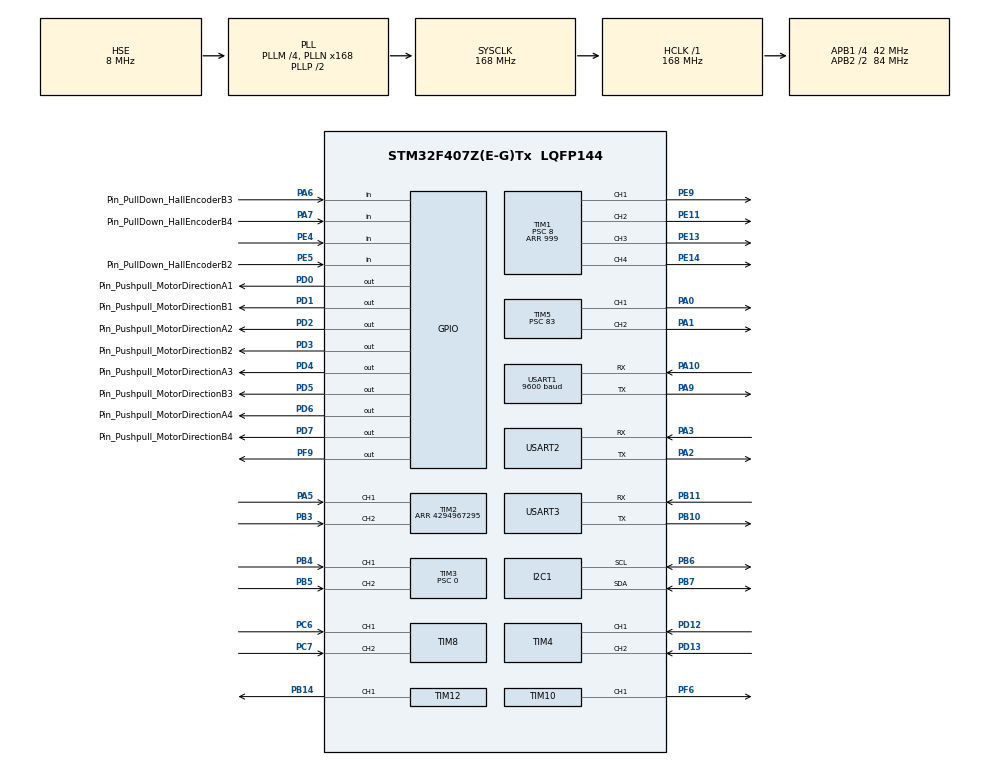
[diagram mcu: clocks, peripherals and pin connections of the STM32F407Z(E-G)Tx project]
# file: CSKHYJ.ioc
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Mcu.Family=STM32F4
Mcu.Name=STM32F407Z(E-G)Tx
Mcu.Package=LQFP144
NVIC.PriorityGroup=NVIC_PRIORITYGROUP_4
NVIC.TIM1_UP_TIM10_IRQn=true\:0\:0\:false\:false\:true\:true\:true\:true
NVIC.TIM5_IRQn=true\:2\:0\:true\:false\:true\:true\:true\:true
NVIC.TIM6_DAC_IRQn=true\:0\:0\:false\:false\:true\:true\:true\:true
NVIC.USART1_IRQn=true\:0\:0\:true\:false\:true\:true\:true\:true
NVIC.USART3_IRQn=true\:0\:0\:true\:false\:true\:true\:true\:true
PA0-WKUP.Signal=S_TIM5_CH1
PA1.Signal=S_TIM5_CH2
PA10.Mode=Asynchronous
PA10.Signal=USART1_RX
PA13.Mode=Serial_Wire
PA13.Signal=SYS_JTMS-SWDIO
PA14.Mode=Serial_Wire
PA14.Signal=SYS_JTCK-SWCLK
PA2.Mode=Asynchronous
PA2.Signal=USART2_TX
PA3.Mode=Asynchronous
PA3.Signal=USART2_RX
PA5.GPIO_PuPd=GPIO_PULLUP
PA5.Signal=S_TIM2_CH1_ETR
PA6.GPIO_Label=Pin_PullDown_HallEncoderB3
PA6.GPIO_PuPd=GPIO_PULLUP
PA6.Signal=GPIO_Input
PA7.GPIO_Label=Pin_PullDown_HallEncoderB4
PA7.GPIO_PuPd=GPIO_PULLUP
PA7.Signal=GPIO_Input
PA9.Mode=Asynchronous
PA9.Signal=USART1_TX
PB10.Mode=Asynchronous
PB10.Signal=USART3_TX
PB11.Mode=Asynchronous
PB11.Signal=USART3_RX
PB14.Signal=S_TIM12_CH1
PB3.GPIO_PuPd=GPIO_PULLUP
PB3.Signal=S_TIM2_CH2
PB4.GPIO_PuPd=GPIO_PULLUP
PB4.Signal=S_TIM3_CH1
PB5.GPIO_PuPd=GPIO_PULLUP
PB5.Signal=S_TIM3_CH2
PB6.GPIO_Pu=GPIO_PULLUP
PB6.Mode=I2C
PB6.Signal=I2C1_SCL
PB7.GPIO_Pu=GPIO_PULLUP
PB7.Mode=I2C
PB7.Signal=I2C1_SDA
PC6.GPIO_PuPd=GPIO_PULLUP
PC6.Signal=S_TIM8_CH1
PC7.GPIO_PuPd=GPIO_PULLUP
PC7.Signal=S_TIM8_CH2
PD0.GPIO_Label=Pin_Pushpull_MotorDirectionA1
PD0.Signal=GPIO_Output
PD1.GPIO_Label=Pin_Pushpull_MotorDirectionB1
PD1.Signal=GPIO_Output
PD12.GPIO_PuPd=GPIO_PULLUP
PD12.Signal=S_TIM4_CH1
PD13.GPIO_PuPd=GPIO_PULLUP
PD13.Signal=S_TIM4_CH2
PD2.GPIO_Label=Pin_Pushpull_MotorDirectionA2
PD2.Signal=GPIO_Output
PD3.GPIO_Label=Pin_Pushpull_MotorDirectionB2
PD3.Signal=GPIO_Output
PD4.GPIO_Label=Pin_Pushpull_MotorDirectionA3
PD4.Signal=GPIO_Output
PD5.GPIO_Label=Pin_Pushpull_MotorDirectionB3
PD5.Signal=GPIO_Output
PD6.GPIO_Label=Pin_Pushpull_MotorDirectionA4
PD6.Signal=GPIO_Output
PD7.GPIO_Label=Pin_Pushpull_MotorDirectionB4
PD7.Signal=GPIO_Output
PE11.Signal=S_TIM1_CH2
PE13.Signal=S_TIM1_CH3
PE14.Signal=S_TIM1_CH4
PE4.Signal=GPIO_Input
PE5.GPIO_Label=Pin_PullDown_HallEncoderB2
PE5.GPIO_PuPd=GPIO_PULLUP
PE5.Signal=GPIO_Input
PE9.Signal=S_TIM1_CH1
PF6.Signal=S_TIM10_CH1
PF9.Signal=GPIO_Output
PH0-OSC_IN.Mode=HSE-External-Oscillator
PH0-OSC_IN.Signal=RCC_OSC_IN
PH1-OSC_OUT.Mode=HSE-External-Oscillator
PH1-OSC_OUT.Signal=RCC_OSC_OUT
ProjectManager.HeapSize=0x200
ProjectManager.StackSize=0x400
ProjectManager.TargetToolchain=MDK-ARM V5.32
RCC.48MHZClocksFreq_Value=84000000
RCC.AHBFreq_Value=168000000
RCC.APB1CLKDivider=RCC_HCLK_DIV4
RCC.APB1Freq_Value=42000000
RCC.APB1TimFreq_Value=84000000
RCC.APB2CLKDivider=RCC_HCLK_DIV2
RCC.APB2Freq_Value=84000000
RCC.APB2TimFreq_Value=168000000
RCC.CortexFreq_Value=168000000
RCC.HCLKFreq_Value=168000000
RCC.HSE_VALUE=8000000
RCC.HSI_VALUE=16000000
RCC.LSE_VALUE=32768
RCC.PLLM=4
RCC.PLLN=168
RCC.PLLSourceVirtual=RCC_PLLSOURCE_HSE
RCC.SYSCLKFreq_VALUE=168000000
RCC.SYSCLKSource=RCC_SYSCLKSOURCE_PLLCLK
RCC.VCOOutputFreq_Value=336000000
SH.S_TIM10_CH1.0=TIM10_CH1,PWM Generation1 CH1
SH.S_TIM12_CH1.0=TIM12_CH1,PWM Generation1 CH1
SH.S_TIM1_CH1.0=TIM1_CH1,PWM Generation1 CH1
SH.S_TIM1_CH2.0=TIM1_CH2,PWM Generation2 CH2
SH.S_TIM1_CH3.0=TIM1_CH3,PWM Generation3 CH3
SH.S_TIM1_CH4.0=TIM1_CH4,PWM Generation4 CH4
SH.S_TIM2_CH1_ETR.0=TIM2_CH1,Encoder_Interface
SH.S_TIM2_CH2.0=TIM2_CH2,Encoder_Interface
SH.S_TIM3_CH1.0=TIM3_CH1,Encoder_Interface
SH.S_TIM3_CH2.0=TIM3_CH2,Encoder_Interface
SH.S_TIM4_CH1.0=TIM4_CH1,Encoder_Interface
SH.S_TIM4_CH2.0=TIM4_CH2,Encoder_Interface
SH.S_TIM5_CH1.0=TIM5_CH1,PWM Generation1 CH1
SH.S_TIM5_CH2.0=TIM5_CH2,PWM Generation2 CH2
SH.S_TIM8_CH1.0=TIM8_CH1,Encoder_Interface
SH.S_TIM8_CH2.0=TIM8_CH2,Encoder_Interface
TIM1.Channel-PWM\ Generation1\ CH1=TIM_CHANNEL_1
TIM1.Channel-PWM\ Generation2\ CH2=TIM_CHANNEL_2
TIM1.Channel-PWM\ Generation3\ CH3=TIM_CHANNEL_3
TIM1.Channel-PWM\ Generation4\ CH4=TIM_CHANNEL_4
TIM1.Period=999
TIM1.Prescaler=8
TIM10.Channel=TIM_CHANNEL_1
TIM10.Period=33599
TIM12.Channel-PWM\ Generation1\ CH1=TIM_CHANNEL_1
TIM12.Period=19999
TIM12.Prescaler=83
TIM2.EncoderMode=TIM_ENCODERMODE_TI12
TIM2.IC1Filter=4
TIM2.IC2Filter=4
TIM2.Period=4294967295
TIM3.EncoderMode=TIM_ENCODERMODE_TI12
TIM3.IC1Filter=4
TIM3.IC2Filter=4
TIM3.Period=65535
TIM3.Prescaler=0
TIM4.EncoderMode=TIM_ENCODERMODE_TI12
TIM4.IC1Filter=4
TIM4.IC2Filter=4
TIM5.Channel-PWM\ Generation1\ CH1=TIM_CHANNEL_1
TIM5.Channel-PWM\ Generation2\ CH2=TIM_CHANNEL_2
TIM5.Period=19999
TIM5.Prescaler=83
TIM6.Period=19999
TIM6.Prescaler=83
TIM8.EncoderMode=TIM_ENCODERMODE_TI12
TIM8.IC1Filter=4
TIM8.IC2Filter=4
USART1.BaudRate=9600
USART1.VirtualMode=VM_ASYNC
USART2.VirtualMode=VM_ASYNC
USART3.VirtualMode=VM_ASYNC
VP_TIM10_VS_ClockSourceINT.Mode=Enable_Timer
VP_TIM12_VS_ClockSourceINT.Mode=Internal
VP_TIM1_VS_ClockSourceINT.Mode=Internal
VP_TIM5_VS_ClockSourceINT.Mode=Internal
VP_TIM6_VS_ClockSourceINT.Mode=Enable_Timer
board=custom

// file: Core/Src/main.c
/* USER CODE BEGIN Header */
/**
  ******************************************************************************
  * @file           : main.c
  * @brief          : Main program body
  ******************************************************************************
  */
/* USER CODE END Header */
#include "main.h"
#include "i2c.h"
#include "tim.h"
#include "usart.h"
#include "gpio.h"

/* USER CODE BEGIN Includes */
#include "Move.hpp"
#include "ArmTask.hpp"
#include "arm.h"
/* USER CODE END Includes */

void SystemClock_Config(void);

int main(void)
{

  /* MCU Configuration--------------------------------------------------------*/

  /* Reset of all peripherals, Initializes the Flash interface and the Systick. */
  HAL_Init();

  /* Configure the system clock */
  SystemClock_Config();

  /* Initialize all configured peripherals */
  MX_GPIO_Init();
  MX_TIM1_Init();
  MX_TIM5_Init();
  MX_USART1_UART_Init();
  MX_I2C1_Init();
  MX_TIM2_Init();
  MX_USART2_UART_Init();
  MX_TIM3_Init();
  MX_TIM4_Init();
  MX_TIM8_Init();
  MX_TIM6_Init();
  MX_TIM10_Init();
  MX_TIM12_Init();
  MX_USART3_UART_Init();
  /* USER CODE BEGIN 2 */
  Move_Init();
  ArmTask_Init();
  /* USER CODE END 2 */

  /* Infinite loop */
  while (1)
  {

    /* USER CODE BEGIN 3 */
    Move_Process();
    /*
     * 临时停用机械臂任务状态机。
     * 当前 0x05 / 0x08 命令由 Community 直接回传 0x83 / 0x85。
     */
    /* ArmTask_Process(); */
  }
  /* USER CODE END 3 */
}

void SystemClock_Config(void)
{
  RCC_OscInitTypeDef RCC_OscInitStruct = {0};
  RCC_ClkInitTypeDef RCC_ClkInitStruct = {0};

  /** Configure the main internal regulator output voltage
  */
  __HAL_RCC_PWR_CLK_ENABLE();
  __HAL_PWR_VOLTAGESCALING_CONFIG(PWR_REGULATOR_VOLTAGE_SCALE1);

  /** Initializes the RCC Oscillators according to the specified parameters
  * in the RCC_OscInitTypeDef structure.
  */
  RCC_OscInitStruct.OscillatorType = RCC_OSCILLATORTYPE_HSE;
  RCC_OscInitStruct.HSEState = RCC_HSE_ON;
  RCC_OscInitStruct.PLL.PLLState = RCC_PLL_ON;
  RCC_OscInitStruct.PLL.PLLSource = RCC_PLLSOURCE_HSE;
  RCC_OscInitStruct.PLL.PLLM = 4;
  RCC_OscInitStruct.PLL.PLLN = 168;
  RCC_OscInitStruct.PLL.PLLP = RCC_PLLP_DIV2;
  RCC_OscInitStruct.PLL.PLLQ = 4;
  if (HAL_RCC_OscConfig(&RCC_OscInitStruct) != HAL_OK)
  {
    Error_Handler();
  }

  /** Initializes the CPU, AHB and APB buses clocks
  */
  RCC_ClkInitStruct.ClockType = RCC_CLOCKTYPE_HCLK|RCC_CLOCKTYPE_SYSCLK
                              |RCC_CLOCKTYPE_PCLK1|RCC_CLOCKTYPE_PCLK2;
  RCC_ClkInitStruct.SYSCLKSource = RCC_SYSCLKSOURCE_PLLCLK;
  RCC_ClkInitStruct.AHBCLKDivider = RCC_SYSCLK_DIV1;
  RCC_ClkInitStruct.APB1CLKDivider = RCC_HCLK_DIV4;
  RCC_ClkInitStruct.APB2CLKDivider = RCC_HCLK_DIV2;

  if (HAL_RCC_ClockConfig(&RCC_ClkInitStruct, FLASH_LATENCY_5) != HAL_OK)
  {
    Error_Handler();
  }
}

/* USER CODE BEGIN 4 */

void HAL_TIM_PeriodElapsedCallback(TIM_HandleTypeDef *htim)
{
  Move_TIM_Callback(htim);
}

void HAL_TIM_PWM_PulseFinishedCallback(TIM_HandleTypeDef *htim)
{
  Arm_TIM_PWM_PulseFinishedCallback(htim);
}

void HAL_UART_RxCpltCallback(UART_HandleTypeDef *huart)
{
  Move_UART_RxCpltCallback(huart);
}

void HAL_UART_ErrorCallback(UART_HandleTypeDef *huart)
{
  Move_UART_ErrorCallback(huart);
}

/* USER CODE END 4 */

void Error_Handler(void)
{
  __disable_irq();
  while (1)
  {
  }
}
